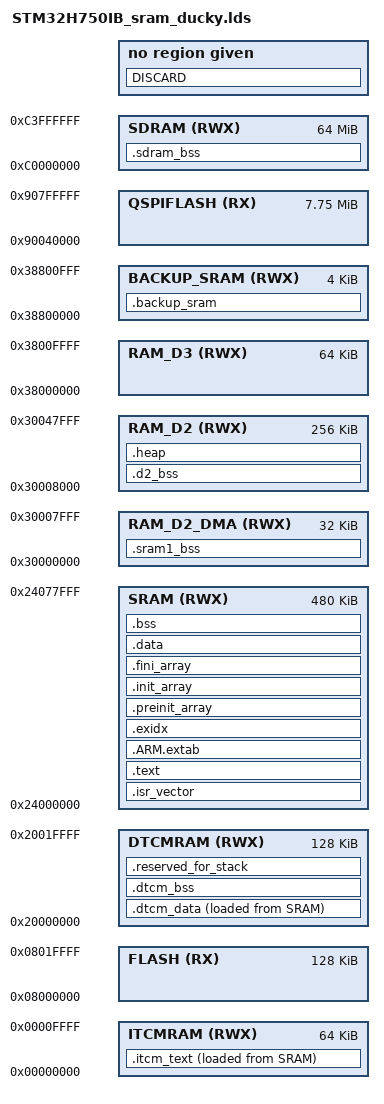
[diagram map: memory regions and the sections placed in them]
/* libDaisy core/STM32H750IB_sram.lds (BOOT_SRAM) for ducky: .data/.bss moved to AXI SRAM, plus .dtcm_data and
   .itcm_text (loaded from SRAM, copied at boot by src/memory.cpp), .dtcm_bss (NOLOAD, zeroed at boot by
   src/memory.cpp), .sdram_bss (NOLOAD: the parsed presets) and .d2_bss (NOLOAD, reserved for later milestones).
   DTCM holds the explicitly placed hot state and the main stack, which keeps a 16 KB reserve (.reserved_for_stack):
   DTCM overflow is a link error. Output sections no object places anything in are left out. */
/* Generated by LinkerScriptGenerator [http://visualgdb.com/tools/LinkerScriptGenerator]
 * Target: STM32H750IB
 * The file is provided under the BSD license.
 */

ENTRY(Reset_Handler)

MEMORY
{
	FLASH       (RX)  : ORIGIN = 0x08000000, LENGTH = 128K
	DTCMRAM     (RWX) : ORIGIN = 0x20000000, LENGTH = 128K
	SRAM        (RWX) : ORIGIN = 0x24000000, LENGTH = 512K - 32K
	RAM_D2_DMA  (RWX) : ORIGIN = 0x30000000, LENGTH = 32K
	RAM_D2      (RWX) : ORIGIN = 0x30008000, LENGTH = 256K
	RAM_D3      (RWX) : ORIGIN = 0x38000000, LENGTH = 64K
	BACKUP_SRAM (RWX) : ORIGIN = 0x38800000, LENGTH = 4K
	ITCMRAM     (RWX) : ORIGIN = 0x00000000, LENGTH = 64K
	SDRAM       (RWX) : ORIGIN = 0xc0000000, LENGTH = 64M
	QSPIFLASH   (RX)  : ORIGIN = 0x90040000, LENGTH = 7936K
}

_estack = 0x20020000;

SECTIONS
{
	.isr_vector :
	{
		. = ALIGN(4);
		KEEP(*(.isr_vector))
		. = ALIGN(4);
	} > SRAM

	.text :
	{
		. = ALIGN(4);
		_stext = .;

		*(.text)
		*(.text*)
		*(.rodata)
		*(.rodata*)
		*(.glue_7)
		*(.glue_7t)
		KEEP(*(.init))
		KEEP(*(.fini))
		. = ALIGN(4);
		_etext = .;

	} > SRAM

	.ARM.extab :
	{
		. = ALIGN(4);
		*(.ARM.extab)
		*(.gnu.linkonce.armextab.*)
		. = ALIGN(4);
	} > SRAM

	.exidx :
	{
		. = ALIGN(4);
		PROVIDE(__exidx_start = .);
		*(.ARM.exidx*)
		. = ALIGN(4);
		PROVIDE(__exidx_end = .);
	} > SRAM

	.ARM.attributes 0 : { *(.ARM.attributes) }

	.preinit_array :
	{
		PROVIDE_HIDDEN(__preinit_array_start = .);
		KEEP(*(.preinit_array*))
		PROVIDE_HIDDEN(__preinit_array_end = .);
	} > SRAM

	.init_array :
	{
		PROVIDE_HIDDEN(__init_array_start = .);
		KEEP(*(SORT(.init_array.*)))
		KEEP(*(.init_array*))
		PROVIDE_HIDDEN(__init_array_end = .);
	} > SRAM

	.fini_array :
	{
		PROVIDE_HIDDEN(__fini_array_start = .);
		KEEP(*(.fini_array*))
		KEEP(*(SORT(.fini_array.*)))
		PROVIDE_HIDDEN(__fini_array_end = .);
	} > SRAM

	.sram1_bss (NOLOAD) :
	{
		. = ALIGN(4);
		_ssram1_bss = .;

		PROVIDE(__sram1_bss_start__ = _sram1_bss);
		*(.sram1_bss)
		*(.sram1_bss*)
		. = ALIGN(4);
		_esram1_bss = .;

		PROVIDE(__sram1_bss_end__ = _esram1_bss);
	} > RAM_D2_DMA

	.data :
	{
		. = ALIGN(4);
		_sdata = .;

		PROVIDE(__data_start__ = _sdata);
		*(.data)
		*(.data*)
		. = ALIGN(4);
		_edata = .;

		PROVIDE(__data_end__ = _edata);
	} > SRAM

	_sidata = LOADADDR(.data);

	/* ducky: hot state in DTCM, loaded from SRAM and copied at boot (memory.cpp), so any initialiser works. It has a
	   load image, so it is data, not bss. */
	.dtcm_data :
	{
		. = ALIGN(4);
		*(.dtcm_data)
		*(.dtcm_data*)
		. = ALIGN(4);
	} > DTCMRAM AT > SRAM
	_dtcm_data_start = ADDR(.dtcm_data);
	_dtcm_data_end = ADDR(.dtcm_data) + SIZEOF(.dtcm_data);
	_dtcm_data_load = LOADADDR(.dtcm_data);

	/* ducky: zero-initialised hot state in DTCM. NOLOAD, so it has no load image; zeroed at boot (memory.cpp). */
	.dtcm_bss (NOLOAD) :
	{
		. = ALIGN(4);
		*(.dtcm_bss)
		*(.dtcm_bss*)
		. = ALIGN(4);
	} > DTCMRAM
	_dtcm_bss_start = ADDR(.dtcm_bss);
	_dtcm_bss_end = ADDR(.dtcm_bss) + SIZEOF(.dtcm_bss);

	/* ducky: hot code in ITCM, loaded from SRAM and copied at boot (memory.cpp). */
	.itcm_text :
	{
		. = . + 0x100;   /* no function at address 0, which would compare equal to a null function pointer */
		. = ALIGN(4);
		*(.itcm_text)
		*(.itcm_text*)
		. = ALIGN(4);
	} > ITCMRAM AT > SRAM
	_itcm_text_start = ADDR(.itcm_text);
	_itcm_text_end = ADDR(.itcm_text) + SIZEOF(.itcm_text);
	_itcm_text_load = LOADADDR(.itcm_text);

	.bss (NOLOAD) :
	{
		. = ALIGN(4);
		_sbss = .;

		PROVIDE(__bss_start__ = _sbss);
		*(.bss)
		*(.bss*)
		*(COMMON)
		. = ALIGN(4);
		_ebss = .;

		PROVIDE(__bss_end__ = _ebss);
	} > SRAM

	.sdram_bss (NOLOAD) :
	{
		. = ALIGN(4);
		_ssdram_bss = .;

		PROVIDE(__sdram_bss_start = _ssdram_bss);
		*(.sdram_bss)
		*(.sdram_bss*)
		. = ALIGN(4);
		_esdram_bss = .;

		PROVIDE(__sdram_bss_end = _esdram_bss);
	} > SDRAM

	.backup_sram (NOLOAD) :
	{
		. = ALIGN(4);
		_sbackup_sram = .;

		PROVIDE(__backup_sram_start = _sbackup_sram);
		*(.backup_sram)
		*(.backup_sram*)
		. = ALIGN(4);
		_ebackup_sram = .;

		PROVIDE(__backup_sram_end = _ebackup_sram);
	} > BACKUP_SRAM

	/* ducky: reserved for later milestones. Not zeroed by startup; its owner clears it. */
	.d2_bss (NOLOAD) :
	{
		. = ALIGN(4);
		*(.d2_bss)
		*(.d2_bss*)
		. = ALIGN(4);
	} > RAM_D2

	.heap (NOLOAD) :
	{
		. = ALIGN(4);
		PROVIDE(__heap_start__ = .);
		PROVIDE(__heap_start = .);
		KEEP(*(.heap))
		. = ALIGN(4);
		PROVIDE(__heap_end = .);
		PROVIDE(__heap_end__ = .);
	} > RAM_D2

	PROVIDE(end = .);

	/* ducky: the main stack's guaranteed 16 KB. The stack grows down from _estack (0x20020000, the top of DTCM)
	   toward the placed state; reserving 16 KB after that state makes DTCM overflow a link error. */
	.reserved_for_stack (NOLOAD) :
	{
		. = ALIGN(8);
		. = . + 16K;
	} > DTCMRAM

    DISCARD :
    {
        libc.a ( * )
        libm.a ( * )
        libgcc.a ( * )
    }

}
